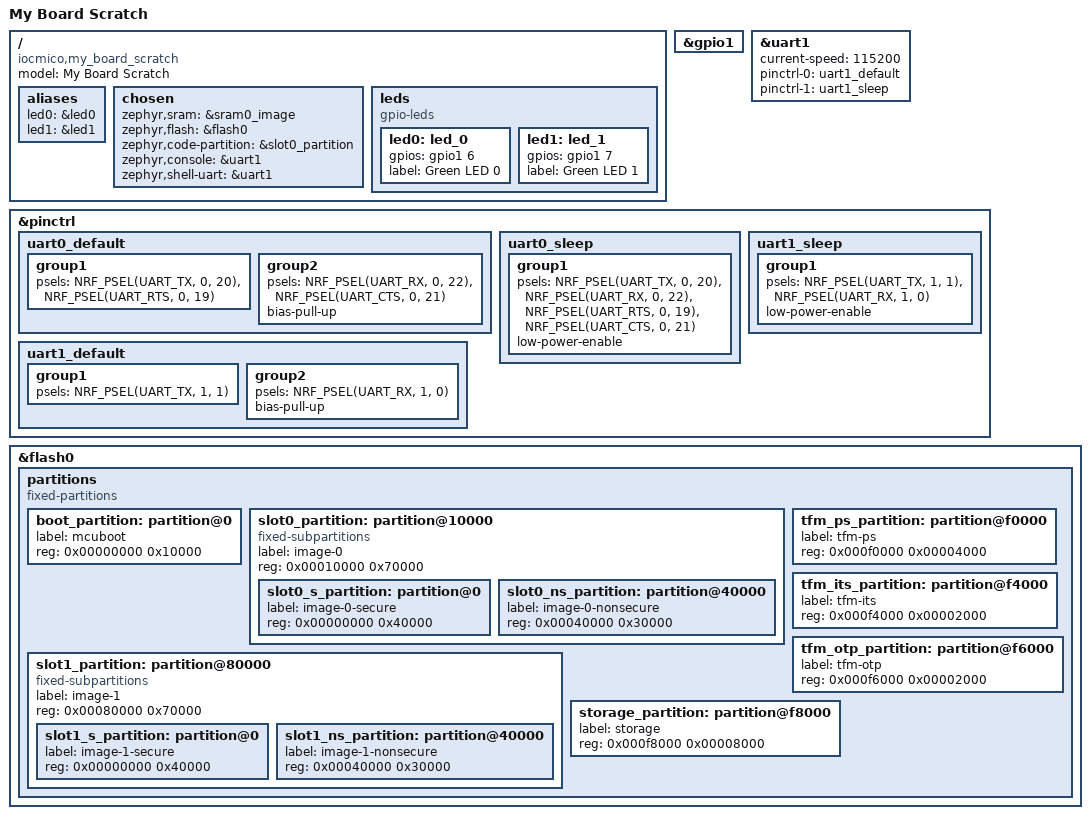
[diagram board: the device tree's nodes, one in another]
/dts-v1/;


#include <nordic/nrf5340_cpuapp_qkaa.dtsi>
#include <nordic/nrf5340_cpuapp_partition.dtsi>

/{
	model = "My Board Scratch";
	compatible = "iocmico,my_board_scratch";

	aliases{
		led0 = &led0;
		led1 = &led1;

	};
	chosen {
		zephyr,sram = &sram0_image;
		zephyr,flash = &flash0;
		zephyr,code-partition = &slot0_partition;
		zephyr,console = &uart1;
		zephyr,shell-uart = &uart1;
	};


	leds {
		compatible = "gpio-leds";

		led0: led_0 {
			gpios = <&gpio1 6 GPIO_ACTIVE_HIGH>;
			label = "Green LED 0";
		};

		led1: led_1 {
			gpios = <&gpio1 7 GPIO_ACTIVE_HIGH>;
			label = "Green LED 1";
		};
	};
};
&gpio1 {
status = "okay";
};
&uart1 {
	status = "okay";
	current-speed = <115200>;
	pinctrl-0 = <&uart1_default>;
	pinctrl-1 = <&uart1_sleep>;
	pinctrl-names = "default", "sleep";
};
&pinctrl {

	uart0_default: uart0_default {
		group1 {
			psels = <NRF_PSEL(UART_TX, 0, 20)>,
				<NRF_PSEL(UART_RTS, 0, 19)>;
		};

		group2 {
			psels = <NRF_PSEL(UART_RX, 0, 22)>,
				<NRF_PSEL(UART_CTS, 0, 21)>;
			bias-pull-up;
		};
	};

	uart0_sleep: uart0_sleep {
		group1 {
			psels = <NRF_PSEL(UART_TX, 0, 20)>,
				<NRF_PSEL(UART_RX, 0, 22)>,
				<NRF_PSEL(UART_RTS, 0, 19)>,
				<NRF_PSEL(UART_CTS, 0, 21)>;
			low-power-enable;
		};
	};

	uart1_default: uart1_default {
		group1 {
			psels = <NRF_PSEL(UART_TX, 1, 1)>;
		};

		group2 {
			psels = <NRF_PSEL(UART_RX, 1, 0)>;
			bias-pull-up;
		};
	};

	uart1_sleep: uart1_sleep {
		group1 {
			psels = <NRF_PSEL(UART_TX, 1, 1)>,
				<NRF_PSEL(UART_RX, 1, 0)>;
			low-power-enable;
		};
	};

};
&flash0 {
	/*
	* Default Flash planning for nRF5340 series SoCs.
	* This layout matches (by necessity) that in the TF-M repository:
	*
	* 0x0000_0000 BL2 - MCUBoot (64 KB)
	* 0x0001_0000 Primary image area (448 KB):
	*    0x0001_0000 Secure     image primary (256 KB)
	*    0x0005_0000 Non-secure image primary (192 KB)
	* 0x0008_0000 Secondary image area (448 KB):
	*    0x0008_0000 Secure     image secondary (256 KB)
	*    0x000c_0000 Non-secure image secondary (192 KB)
	* 0x000f_0000 Protected Storage Area (16 KB)
	* 0x000f_4000 Internal Trusted Storage Area (8 KB)
	* 0x000f_6000 OTP / NV counters area (8 KB)
	* 0x000f_8000 Non-secure storage, used when built with NRF_NS_STORAGE=ON,
	*             otherwise unused (32 KB)
	*/
	partitions {
		compatible = "fixed-partitions";
		#address-cells = <1>;
		#size-cells = <1>;

		boot_partition: partition@0 {
			label = "mcuboot";
			reg = <0x00000000 0x10000>;
		};

		slot0_partition: partition@10000 {
			compatible = "fixed-subpartitions";
			label = "image-0";
			reg = <0x00010000 0x70000>;
			ranges = <0x0 0x10000 0x70000>;
			#address-cells = <1>;
			#size-cells = <1>;

			slot0_s_partition: partition@0 {
				label = "image-0-secure";
				reg = <0x00000000 0x40000>;
			};

			slot0_ns_partition: partition@40000 {
				label = "image-0-nonsecure";
				reg = <0x00040000 0x30000>;
			};
		};

		slot1_partition: partition@80000 {
			compatible = "fixed-subpartitions";
			label = "image-1";
			reg = <0x00080000 0x70000>;
			ranges = <0x0 0x80000 0x70000>;
			#address-cells = <1>;
			#size-cells = <1>;

			slot1_s_partition: partition@0 {
				label = "image-1-secure";
				reg = <0x00000000 0x40000>;
			};

			slot1_ns_partition: partition@40000 {
				label = "image-1-nonsecure";
				reg = <0x00040000 0x30000>;
			};
		};

		tfm_ps_partition: partition@f0000 {
			label = "tfm-ps";
			reg = <0x000f0000 0x00004000>;
		};

		tfm_its_partition: partition@f4000 {
			label = "tfm-its";
			reg = <0x000f4000 0x00002000>;
		};

		tfm_otp_partition: partition@f6000 {
			label = "tfm-otp";
			reg = <0x000f6000 0x00002000>;
		};

		storage_partition: partition@f8000 {
			label = "storage";
			reg = <0x000f8000 0x00008000>;
		};
	};
};

